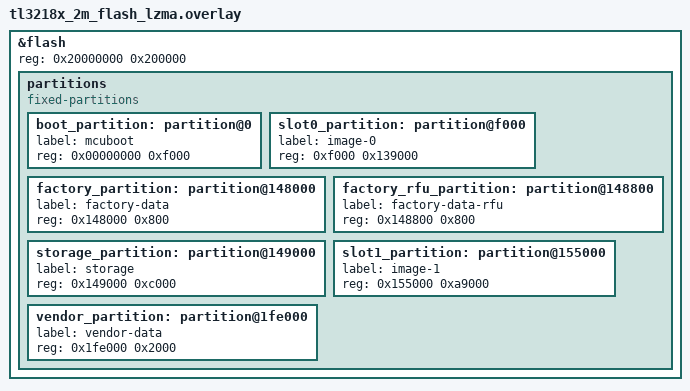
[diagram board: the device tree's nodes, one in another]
&flash {
	reg = <0x20000000 0x200000>;

	/delete-node/ partitions;
	partitions {
		compatible = "fixed-partitions";
		#address-cells = <1>;
		#size-cells = <1>;

		boot_partition: partition@0 {
			label = "mcuboot";
			reg = <0x00000000 0xf000>;
		};
		slot0_partition: partition@f000 {
			label = "image-0";
			reg = <0xf000 0x139000>;
		};
		factory_partition: partition@148000 {
			label = "factory-data";
			reg = <0x148000 0x800>;
		};
		factory_rfu_partition: partition@148800 {
			label = "factory-data-rfu";
			reg = <0x148800 0x800>;
		};
		storage_partition: partition@149000 {
			label = "storage";
			reg = <0x149000 0xc000>;
		};
		slot1_partition: partition@155000 {
			label = "image-1";
			reg = <0x155000 0xa9000>;
		};
		vendor_partition: partition@1fe000 {
			label = "vendor-data";
			reg = <0x1fe000 0x2000>;
		};
	};
};
